# SCR_TC3xx register map
Vendor: Infineon; File version: 1.0
AURIX TC3xx standby controller (SCR, XC800): special function registers at the SCR debug monitor's virtual addresses
Registers are 8-bit, read-write, reset 0x0 unless marked. A register's access mark holds for its fields unless they carry their own. Offsets are from the block's base; lines under a group give offsets from that group; [hi:lo] are bit positions; {n}, {i} and the like mark numbered series; 'fields as' and 'values as' point back to an identical list; <NAME> marks a mode.

## Memory map
0x00040000 SCR_SYSTEM blocks up to offset 0x9 — SCR System control: SFR map (RMAP), bit protection, XRAM address extension
0x00040000 SCR_CPU blocks up to offset 0x5A — SCR XC800 CPU control: extended operation (TRAP enable, DPTR select) and power control
0x00040000 SCR_INT blocks up to offset 0x5D — SCR Interrupt enable and priority
0x00040000 SCR_SCU blocks up to offset 0x1717A — SCR System control unit: SFR paging, clocks, resets, power management, NMI, external interrupts, TriCore data exchange, input selection
0x00040000 SCR_WDT blocks up to offset 0x6 — SCR Watchdog timer
0x00040000 SCR_PORT blocks up to offset 0x10F1E — SCR General purpose I/O ports SCR_P00 (P33.0-P33.7) and SCR_P01 (P34.1, P33.8-P33.15)
0x00040000 SCR_RTC blocks up to offset 0x6A — SCR Real-time clock
0x00040000 SCR_T01 blocks up to offset 0x4F — SCR Timer 0 and timer 1
0x00040000 SCR_T2CCU blocks up to offset 0x24744 — SCR Timer 2 and capture/compare unit
0x00040000 SCR_UART blocks up to offset 0x40 — SCR Universal asynchronous receiver/transmitter (with LIN support)
0x00040000 SCR_SSC blocks up to offset 0xF — SCR Synchronous serial channel
0x00040000 SCR_WCAN blocks up to offset 0x1B838 — SCR Wake-up CAN filter
0x00047100 SCR_ADCOMP blocks up to offset 0x7C — SCR ADC comparator unit

## SCR_SYSTEM — SCR System control: SFR map (RMAP), bit protection, XRAM address extension
Base 0x00040000
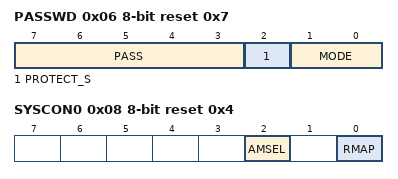
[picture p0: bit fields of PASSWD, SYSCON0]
0x06 PASSWD reset 0x7 — Password Register (SFR 0x86)
  [7:3] PASS — Password Bits. The Bit-Protection Scheme only recognizes three patterns. [w]
    19=PROT_OPEN (Opens access to writing of all protected bits); 21=PROT_CLOSE (Closes access to writing of all protected bits); 24=MODE_EN (Enables writing of the bit field MODE)
  [2] PROTECT_S ro — Bit-Protection Signal Status Bit. This bit shows the status of the protection. [rh]
    0=SOFTWARE_IS_ABLE_TO_WRITE_TO_ALL (Software is able to write to all protected bits); 1=SOFTWARE_IS_UNABLE_TO_WRITE_TO (Software is unable to write to any protected bits (default))
  [1:0] MODE — Bit-Protection Scheme Control Bit. These two bits cannot be written directly. To change the value between 11B and 00B, the bitfield PASS must be written with 11000B, only then the MODE[1:0] will be registered. others, Reserved; do not use [rw]
    0=SCHEME_DIS (Scheme Disabled); 3=SCHEME_EN3 (Scheme Enabled)
0x07 XADDRH — On-Chip XRAM Address Higher Order (SFR 0x87)
  [7:0] ADDRH — Higher Order of On-chip XRAM Address. The range for SCR is from 00H. [rw]
0x08 SYSCON0 reset 0x4 — System Control Register 0 (SFR 0x88)
  [2] AMSEL — Active Memory Map Select. [rw]
    0=ACTIVE_MEMORY_MAP_0_BOOT_ROM_IS (Active memory map 0: Boot ROM is only mapped from 0xD000); 1=ACTIVE_MEMORY_MAP_1_LAST_512 (Active memory map 1: Last 512 bytes of Boot ROM are mapped to both, 0x0000 and 0xD600)
  [0] RMAP — Special Function Register Map Control. [rw]
    0=ACCESS_TO_NON_MAPPED_STANDARD (Access to non-mapped (standard) special function register area); 1=ACCESS_TO_MAPPED_SPECIAL_FUNCTION (Access to mapped special function register area (this setting is not used for applications; therefore, RMAP should be programmed with 0))

## SCR_CPU — SCR XC800 CPU control: extended operation (TRAP enable, DPTR select) and power control
Base 0x00040000
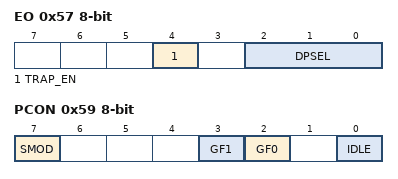
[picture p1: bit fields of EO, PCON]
0x57 EO — Extended Operation Register (SFR 0xD7)
  [4] TRAP_EN — TRAP Enable. [rw]
    0=SEL_MOVC (Select MOVC @(DPTR++),A); 1=SEL_TRAP (Select software TRAP instruction)
  [2:0] DPSEL — Data Pointer Select. These bits are used to select the current data pointer. others, Reserved [rw]
    0=DTPR0 (DPTR0 selected); 1=DTPR1 (DPTR1 selected)
0x59 PCON — Power Control Register (SFR 0xD9)
  [7] SMOD — Double Baud Rate Enable. [rw]
    0=DO_NOT_DOUBLE_THE_BAUD_RATE_OF (Do not double the baud rate of serial interface in mode 2); 1=DOUBLE_THE_BAUD_RATE_OF_SERIAL (Double the baud rate of serial interface in mode 2)
  [3] GF1 — General Purpose Flag Bit 1. [rw]
  [2] GF0 — General Purpose Flag Bit 0. [rw]
  [0] IDLE — Idle Mode Enable. [rw]
    0=DO_NOT_ENTER_IDLE_MODE; 1=ENTER_IDLE_MODE
